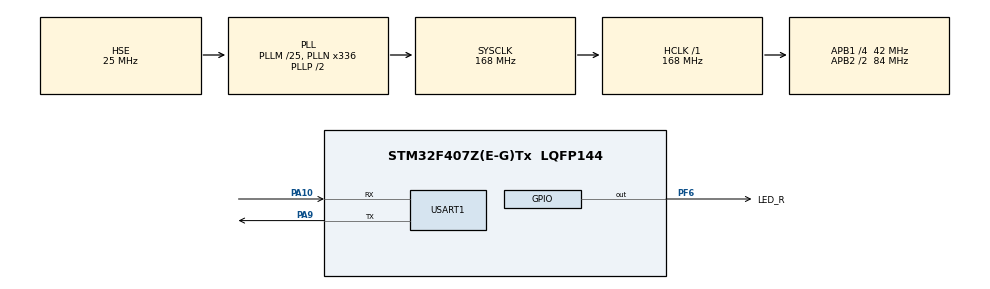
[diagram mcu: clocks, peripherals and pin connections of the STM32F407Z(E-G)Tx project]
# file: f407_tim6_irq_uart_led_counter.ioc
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Mcu.Family=STM32F4
Mcu.Name=STM32F407Z(E-G)Tx
Mcu.Package=LQFP144
NVIC.PriorityGroup=NVIC_PRIORITYGROUP_4
NVIC.TIM6_DAC_IRQn=true\:0\:0\:false\:false\:true\:true\:true\:true
PA10.Mode=Asynchronous
PA10.Signal=USART1_RX
PA13.Mode=Serial_Wire
PA13.Signal=SYS_JTMS-SWDIO
PA14.Mode=Serial_Wire
PA14.Signal=SYS_JTCK-SWCLK
PA9.Mode=Asynchronous
PA9.Signal=USART1_TX
PF6.GPIO_Label=LED_R
PF6.PinState=GPIO_PIN_SET
PF6.Signal=GPIO_Output
PH0-OSC_IN.Mode=HSE-External-Oscillator
PH0-OSC_IN.Signal=RCC_OSC_IN
PH1-OSC_OUT.Mode=HSE-External-Oscillator
PH1-OSC_OUT.Signal=RCC_OSC_OUT
ProjectManager.HeapSize=0x200
ProjectManager.StackSize=0x400
ProjectManager.TargetToolchain=CMake
RCC.48MHZClocksFreq_Value=84000000
RCC.AHBFreq_Value=168000000
RCC.APB1CLKDivider=RCC_HCLK_DIV4
RCC.APB1Freq_Value=42000000
RCC.APB1TimFreq_Value=84000000
RCC.APB2CLKDivider=RCC_HCLK_DIV2
RCC.APB2Freq_Value=84000000
RCC.APB2TimFreq_Value=168000000
RCC.CortexFreq_Value=168000000
RCC.HCLKFreq_Value=168000000
RCC.HSE_VALUE=25000000
RCC.HSI_VALUE=16000000
RCC.LSE_VALUE=32768
RCC.PLLM=25
RCC.PLLN=336
RCC.PLLSourceVirtual=RCC_PLLSOURCE_HSE
RCC.SYSCLKFreq_VALUE=168000000
RCC.SYSCLKSource=RCC_SYSCLKSOURCE_PLLCLK
RCC.VCOOutputFreq_Value=336000000
TIM6.Period=19999
TIM6.Prescaler=8399
USART1.VirtualMode=VM_ASYNC
VP_TIM6_VS_ClockSourceINT.Mode=Enable_Timer
board=custom

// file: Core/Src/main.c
/* USER CODE BEGIN Header */
/**
  ******************************************************************************
  * @file           : main.c
  * @brief          : Main program body
  ******************************************************************************
  * @attention
  *
  * Copyright (c) 2026 STMicroelectronics.
  * All rights reserved.
  *
  * This software is licensed under terms that can be found in the LICENSE file
  * in the root directory of this software component.
  * If no LICENSE file comes with this software, it is provided AS-IS.
  *
  ******************************************************************************
  */
/* USER CODE END Header */
#include "main.h"

/* USER CODE BEGIN Includes */
#include <stdio.h>
/* USER CODE END Includes */

TIM_HandleTypeDef htim6;

UART_HandleTypeDef huart1;

/* USER CODE BEGIN PV */
/* TIM6每次到达2秒时，由中断置1 */
static volatile uint8_t tim6_elapsed_event = 0U;

/* 记录已经过去了多少个2秒 */
static uint32_t count_2s = 0U;
/* USER CODE END PV */

void SystemClock_Config(void);
static void MX_GPIO_Init(void);
static void MX_TIM6_Init(void);
static void MX_USART1_UART_Init(void);
/* USER CODE BEGIN PFP */
static void UART_LogCount(uint32_t count);
/* USER CODE END PFP */

int main(void)
{

  /* MCU Configuration--------------------------------------------------------*/

  /* Reset of all peripherals, Initializes the Flash interface and the Systick. */
  HAL_Init();

  /* Configure the system clock */
  SystemClock_Config();

  /* Initialize all configured peripherals */
  MX_GPIO_Init();
  MX_TIM6_Init();
  MX_USART1_UART_Init();
  /* USER CODE BEGIN 2 */
  /* 红灯为低电平点亮，程序启动时先确保红灯熄灭 */
HAL_GPIO_WritePin(LED_R_GPIO_Port, LED_R_Pin, GPIO_PIN_SET);

/* 以中断方式启动TIM6 */
if (HAL_TIM_Base_Start_IT(&htim6) != HAL_OK)
{
  Error_Handler();
}

/* 向电脑串口发送启动提示 */
{
  const uint8_t message[] =
      "TIM6 internal interrupt started, period = 2 seconds.\r\n";

  HAL_UART_Transmit(
      &huart1,
      (uint8_t *)message,
      sizeof(message) - 1U,
      100U);
}
  /* USER CODE END 2 */

  /* Infinite loop */
  while (1)
  {
    if (tim6_elapsed_event != 0U)
{
  /*
   * 清除事件标志。
   * 中断函数只通知主循环，不在中断里发送串口，
   * 防止中断函数执行时间过长。
   */
  tim6_elapsed_event = 0U;

  /* 每经过2秒，计数值加1 */
  count_2s++;

  /*
   * 翻转红灯：
   * 第1次中断：由高变低，红灯点亮
   * 第2次中断：由低变高，红灯熄灭
   */
  HAL_GPIO_TogglePin(LED_R_GPIO_Port, LED_R_Pin);

  /* 把计数值发送到电脑 */
  UART_LogCount(count_2s);
}
  }
}

void SystemClock_Config(void)
{
  RCC_OscInitTypeDef RCC_OscInitStruct = {0};
  RCC_ClkInitTypeDef RCC_ClkInitStruct = {0};

  /** Configure the main internal regulator output voltage
  */
  __HAL_RCC_PWR_CLK_ENABLE();
  __HAL_PWR_VOLTAGESCALING_CONFIG(PWR_REGULATOR_VOLTAGE_SCALE1);

  /** Initializes the RCC Oscillators according to the specified parameters
  * in the RCC_OscInitTypeDef structure.
  */
  RCC_OscInitStruct.OscillatorType = RCC_OSCILLATORTYPE_HSE;
  RCC_OscInitStruct.HSEState = RCC_HSE_ON;
  RCC_OscInitStruct.PLL.PLLState = RCC_PLL_ON;
  RCC_OscInitStruct.PLL.PLLSource = RCC_PLLSOURCE_HSE;
  RCC_OscInitStruct.PLL.PLLM = 25;
  RCC_OscInitStruct.PLL.PLLN = 336;
  RCC_OscInitStruct.PLL.PLLP = RCC_PLLP_DIV2;
  RCC_OscInitStruct.PLL.PLLQ = 4;
  if (HAL_RCC_OscConfig(&RCC_OscInitStruct) != HAL_OK)
  {
    Error_Handler();
  }

  /** Initializes the CPU, AHB and APB buses clocks
  */
  RCC_ClkInitStruct.ClockType = RCC_CLOCKTYPE_HCLK|RCC_CLOCKTYPE_SYSCLK
                              |RCC_CLOCKTYPE_PCLK1|RCC_CLOCKTYPE_PCLK2;
  RCC_ClkInitStruct.SYSCLKSource = RCC_SYSCLKSOURCE_PLLCLK;
  RCC_ClkInitStruct.AHBCLKDivider = RCC_SYSCLK_DIV1;
  RCC_ClkInitStruct.APB1CLKDivider = RCC_HCLK_DIV4;
  RCC_ClkInitStruct.APB2CLKDivider = RCC_HCLK_DIV2;

  if (HAL_RCC_ClockConfig(&RCC_ClkInitStruct, FLASH_LATENCY_5) != HAL_OK)
  {
    Error_Handler();
  }
}

static void MX_TIM6_Init(void)
{

  TIM_MasterConfigTypeDef sMasterConfig = {0};

  htim6.Instance = TIM6;
  htim6.Init.Prescaler = 8399;
  htim6.Init.CounterMode = TIM_COUNTERMODE_UP;
  htim6.Init.Period = 19999;
  htim6.Init.AutoReloadPreload = TIM_AUTORELOAD_PRELOAD_DISABLE;
  if (HAL_TIM_Base_Init(&htim6) != HAL_OK)
  {
    Error_Handler();
  }
  sMasterConfig.MasterOutputTrigger = TIM_TRGO_RESET;
  sMasterConfig.MasterSlaveMode = TIM_MASTERSLAVEMODE_DISABLE;
  if (HAL_TIMEx_MasterConfigSynchronization(&htim6, &sMasterConfig) != HAL_OK)
  {
    Error_Handler();
  }

}

static void MX_USART1_UART_Init(void)
{

  huart1.Instance = USART1;
  huart1.Init.BaudRate = 115200;
  huart1.Init.WordLength = UART_WORDLENGTH_8B;
  huart1.Init.StopBits = UART_STOPBITS_1;
  huart1.Init.Parity = UART_PARITY_NONE;
  huart1.Init.Mode = UART_MODE_TX_RX;
  huart1.Init.HwFlowCtl = UART_HWCONTROL_NONE;
  huart1.Init.OverSampling = UART_OVERSAMPLING_16;
  if (HAL_UART_Init(&huart1) != HAL_OK)
  {
    Error_Handler();
  }

}

static void MX_GPIO_Init(void)
{
  GPIO_InitTypeDef GPIO_InitStruct = {0};

  /* GPIO Ports Clock Enable */
  __HAL_RCC_GPIOF_CLK_ENABLE();
  __HAL_RCC_GPIOH_CLK_ENABLE();
  __HAL_RCC_GPIOA_CLK_ENABLE();

  /*Configure GPIO pin Output Level */
  HAL_GPIO_WritePin(LED_R_GPIO_Port, LED_R_Pin, GPIO_PIN_SET);

  /*Configure GPIO pin : LED_R_Pin */
  GPIO_InitStruct.Pin = LED_R_Pin;
  GPIO_InitStruct.Mode = GPIO_MODE_OUTPUT_PP;
  GPIO_InitStruct.Pull = GPIO_NOPULL;
  GPIO_InitStruct.Speed = GPIO_SPEED_FREQ_LOW;
  HAL_GPIO_Init(LED_R_GPIO_Port, &GPIO_InitStruct);

}

/* USER CODE BEGIN 4 */
/**
 * @brief  TIM定时周期到达后的HAL回调函数
 * @param  htim 产生中断的定时器句柄
 */
void HAL_TIM_PeriodElapsedCallback(TIM_HandleTypeDef *htim)
{
  /*
   * 一个工程中可能存在多个定时器，
   * 因此必须先判断本次中断是不是TIM6产生的。
   */
  if (htim->Instance == TIM6)
  {
    /*
     * 中断里只设置事件标志。
     * 不在这里调用HAL_UART_Transmit或HAL_Delay。
     */
    tim6_elapsed_event = 1U;
  }
}

/**
 * @brief 把当前计数值发送到串口
 */
static void UART_LogCount(uint32_t count)
{
  char message[80];
  int length;

  length = snprintf(
      message,
      sizeof(message),
      "TIM6 event: Count = %lu, elapsed = %lu seconds\r\n",
      (unsigned long)count,
      (unsigned long)(count * 2U));

  if (length > 0)
  {
    HAL_UART_Transmit(
        &huart1,
        (uint8_t *)message,
        (uint16_t)length,
        100U);
  }
}
/* USER CODE END 4 */

void Error_Handler(void)
{
  __disable_irq();
  while (1)
  {
  }
}
